# LM3S6G65 register map
File version: 7944
Registers are 32-bit, read-write, no defined reset value unless marked. A register's access mark holds for its fields unless they carry their own. Offsets are from the block's base; [hi:lo] are bit positions; {n}, {i} and the like mark numbered series.

## MAC — Register map for MAC peripheral
Base 0x40048000; register names take the prefix MAC
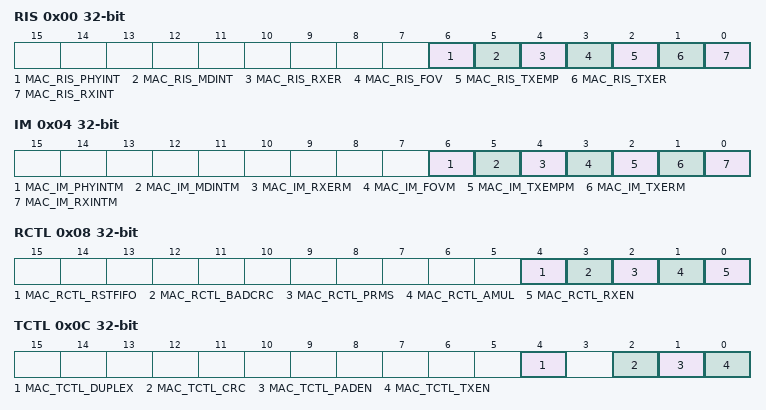
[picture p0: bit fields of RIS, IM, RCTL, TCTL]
0x00 RIS — Ethernet MAC Raw Interrupt Status/Acknowledge
  [6] MAC_RIS_PHYINT — PHY Interrupt
  [5] MAC_RIS_MDINT — MII Transaction Complete
  [4] MAC_RIS_RXER — Receive Error
  [3] MAC_RIS_FOV — FIFO Overrun
  [2] MAC_RIS_TXEMP — Transmit FIFO Empty
  [1] MAC_RIS_TXER — Transmit Error
  [0] MAC_RIS_RXINT — Packet Received
0x04 IM — Ethernet MAC Interrupt Mask
  [6] MAC_IM_PHYINTM — Mask PHY Interrupt
  [5] MAC_IM_MDINTM — Mask MII Transaction Complete
  [4] MAC_IM_RXERM — Mask Receive Error
  [3] MAC_IM_FOVM — Mask FIFO Overrun
  [2] MAC_IM_TXEMPM — Mask Transmit FIFO Empty
  [1] MAC_IM_TXERM — Mask Transmit Error
  [0] MAC_IM_RXINTM — Mask Packet Received
0x08 RCTL — Ethernet MAC Receive Control
  [4] MAC_RCTL_RSTFIFO — Clear Receive FIFO
  [3] MAC_RCTL_BADCRC — Enable Reject Bad CRC
  [2] MAC_RCTL_PRMS — Enable Promiscuous Mode
  [1] MAC_RCTL_AMUL — Enable Multicast Frames
  [0] MAC_RCTL_RXEN — Enable Receiver
0x0C TCTL — Ethernet MAC Transmit Control
  [4] MAC_TCTL_DUPLEX — Enable Duplex Mode
  [2] MAC_TCTL_CRC — Enable CRC Generation
  [1] MAC_TCTL_PADEN — Enable Packet Padding
  [0] MAC_TCTL_TXEN — Enable Transmitter
0x10 DATA — Ethernet MAC Data
  [31:0] MAC_DATA_RXDATA — Receive FIFO Data
0x10 DATA (MAC_ALT view) — Ethernet MAC Data
  [31:0] MAC_DATA_TXDATA — Transmit FIFO Data
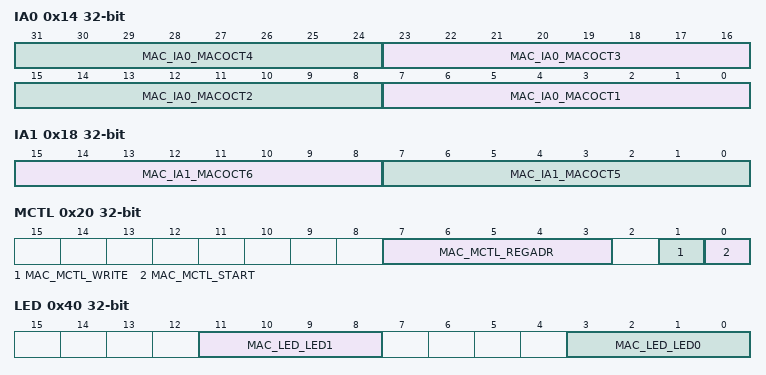
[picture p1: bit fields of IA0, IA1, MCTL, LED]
0x14 IA0 — Ethernet MAC Individual Address 0
  [8n-1:8n-8] MAC_IA0_MACOCT{n} (n=1..4) — MAC Address Octet {n}
0x18 IA1 — Ethernet MAC Individual Address 1
  [15:8] MAC_IA1_MACOCT6 — MAC Address Octet 6
  [7:0] MAC_IA1_MACOCT5 — MAC Address Octet 5
0x1C THR — Ethernet MAC Threshold
  [5:0] MAC_THR_THRESH — Threshold Value
0x20 MCTL — Ethernet MAC Management Control
  [7:3] MAC_MCTL_REGADR — MII Register Address
  [1] MAC_MCTL_WRITE — MII Register Transaction Type
  [0] MAC_MCTL_START — MII Register Transaction Enable
0x24 MDV — Ethernet MAC Management Divider
  [7:0] MAC_MDV_DIV — Clock Divider
0x2C MTXD — Ethernet MAC Management Transmit Data
  [15:0] MAC_MTXD_MDTX — MII Register Transmit Data
0x30 MRXD — Ethernet MAC Management Receive Data
  [15:0] MAC_MRXD_MDRX — MII Register Receive Data
0x34 NP — Ethernet MAC Number of Packets
  [5:0] MAC_NP_NPR — Number of Packets in Receive FIFO
0x38 TR — Ethernet MAC Transmission Request
  [0] MAC_TR_NEWTX — New Transmission
0x40 LED — Ethernet MAC LED Encoding
  [11:8] MAC_LED_LED1 — LED1 Source
    0=MAC_LED_LED1_LINK (Link OK); 1=MAC_LED_LED1_RXTX (RX or TX Activity (Default LED1)); 5=100BASE-TX mode; 6=10BASE-T mode; 7=MAC_LED_LED1_DUPLEX (Full-Duplex); 8=MAC_LED_LED1_LINKACT (Link OK & Blink=RX or TX Activity)
  [3:0] MAC_LED_LED0 — LED0 Source
    0=MAC_LED_LED0_LINK (Link OK (Default LED0)); 1=MAC_LED_LED0_RXTX (RX or TX Activity); 5=100BASE-TX mode; 6=10BASE-T mode; 7=MAC_LED_LED0_DUPLEX (Full-Duplex); 8=MAC_LED_LED0_LINKACT (Link OK & Blink=RX or TX Activity)
0x44 MDIX — Ethernet PHY MDIX
  [0] MAC_MDIX_EN — MDI/MDI-X Enable

## HIB — Register map for HIB peripheral
Base 0x400FC000; register names take the prefix HIB
0x00 RTCC — Hibernation RTC Counter
  [31:0] HIB_RTCC — RTC Counter
0x04 RTCM0 — Hibernation RTC Match 0
  [31:0] HIB_RTCM0 — RTC Match 0
0x08 RTCM1 — Hibernation RTC Match 1
  [31:0] HIB_RTCM1 — RTC Match 1
0x0C RTCLD — Hibernation RTC Load
  [31:0] HIB_RTCLD — RTC Load
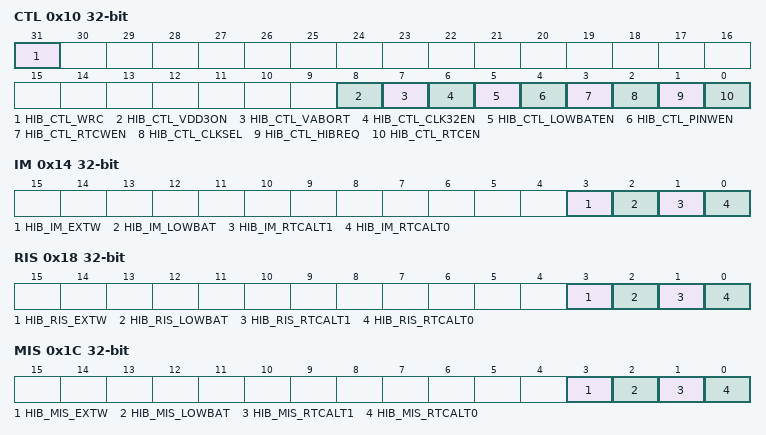
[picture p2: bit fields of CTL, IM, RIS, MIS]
0x10 CTL — Hibernation Control
  [31] HIB_CTL_WRC — Write Complete/Capable
  [8] HIB_CTL_VDD3ON — VDD Powered
  [7] HIB_CTL_VABORT — Power Cut Abort Enable
  [6] HIB_CTL_CLK32EN — Clocking Enable
  [5] HIB_CTL_LOWBATEN — Low Battery Monitoring Enable
  [4] HIB_CTL_PINWEN — External WAKE Pin Enable
  [3] HIB_CTL_RTCWEN — RTC Wake-up Enable
  [2] HIB_CTL_CLKSEL — Hibernation Module Clock Select
  [1] HIB_CTL_HIBREQ — Hibernation Request
  [0] HIB_CTL_RTCEN — RTC Timer Enable
0x14 IM — Hibernation Interrupt Mask
  [3] HIB_IM_EXTW — External Wake-Up Interrupt Mask
  [2] HIB_IM_LOWBAT — Low Battery Voltage Interrupt Mask
  [1] HIB_IM_RTCALT1 — RTC Alert 1 Interrupt Mask
  [0] HIB_IM_RTCALT0 — RTC Alert 0 Interrupt Mask
0x18 RIS — Hibernation Raw Interrupt Status
  [3] HIB_RIS_EXTW — External Wake-Up Raw Interrupt Status
  [2] HIB_RIS_LOWBAT — Low Battery Voltage Raw Interrupt Status
  [1] HIB_RIS_RTCALT1 — RTC Alert 1 Raw Interrupt Status
  [0] HIB_RIS_RTCALT0 — RTC Alert 0 Raw Interrupt Status
0x1C MIS — Hibernation Masked Interrupt Status
  [3] HIB_MIS_EXTW — External Wake-Up Masked Interrupt Status
  [2] HIB_MIS_LOWBAT — Low Battery Voltage Masked Interrupt Status
  [1] HIB_MIS_RTCALT1 — RTC Alert 1 Masked Interrupt Status
  [0] HIB_MIS_RTCALT0 — RTC Alert 0 Masked Interrupt Status
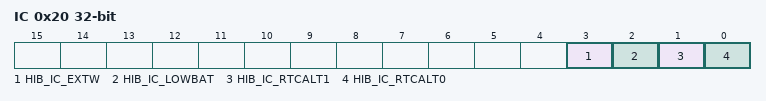
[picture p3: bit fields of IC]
0x20 IC — Hibernation Interrupt Clear
  [3] HIB_IC_EXTW — External Wake-Up Masked Interrupt Clear
  [2] HIB_IC_LOWBAT — Low Battery Voltage Masked Interrupt Clear
  [1] HIB_IC_RTCALT1 — RTC Alert1 Masked Interrupt Clear
  [0] HIB_IC_RTCALT0 — RTC Alert0 Masked Interrupt Clear
0x24 RTCT — Hibernation RTC Trim
  [15:0] HIB_RTCT_TRIM — RTC Trim Value
0x30 DATA — Hibernation Data
  [31:0] HIB_DATA_RTD — Hibernation Module NV Data
